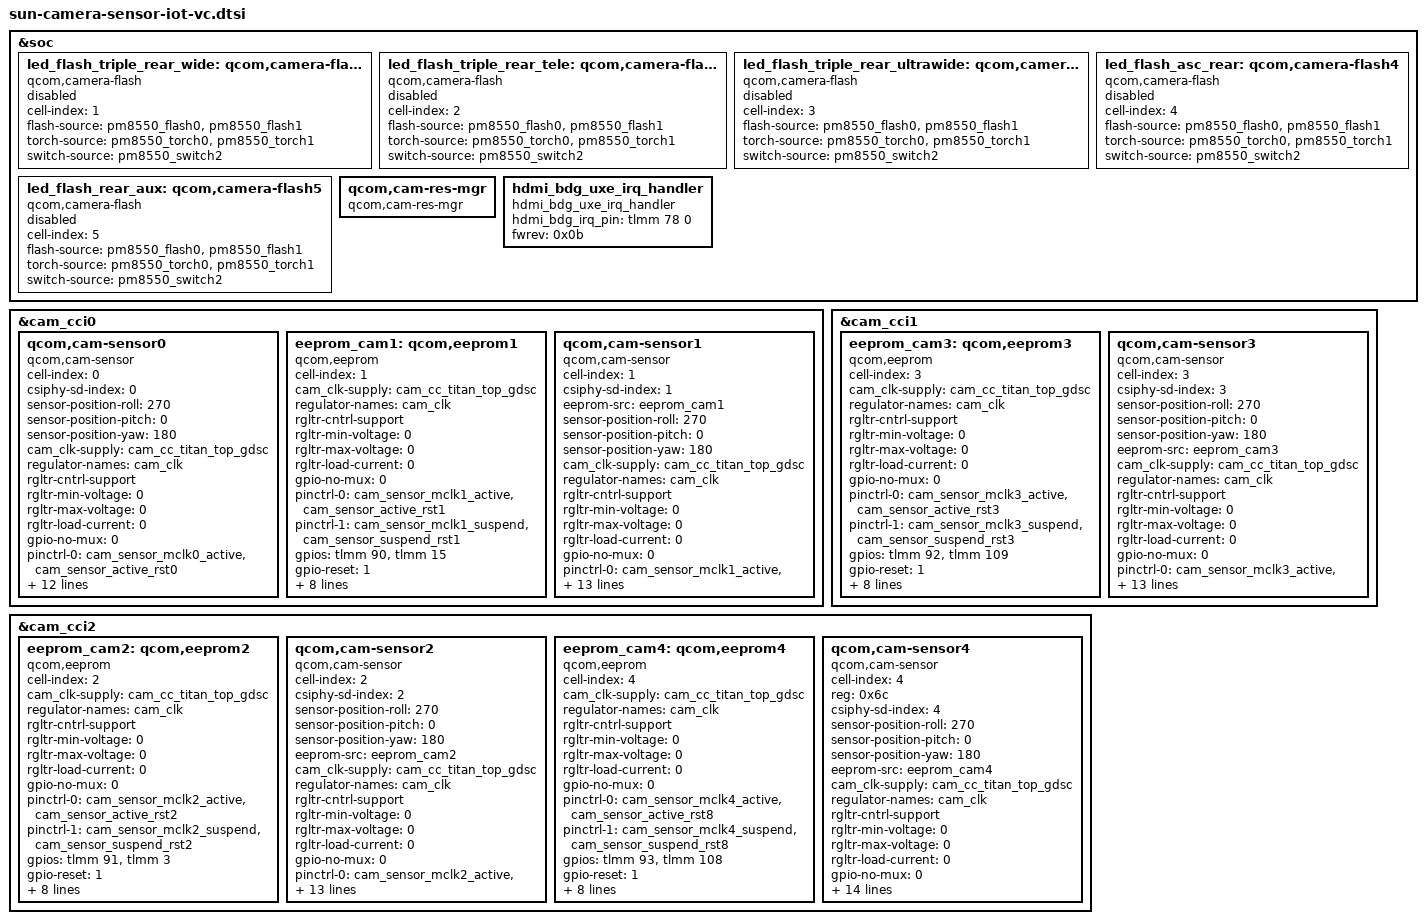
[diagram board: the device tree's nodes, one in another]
// SPDX-License-Identifier: BSD-3-Clause

/*
 * Copyright (c) Qualcomm Technologies, Inc. and/or its subsidiaries.
 */

#include <dt-bindings/msm-camera.h>
&soc {
	led_flash_triple_rear_wide: qcom,camera-flash1 {
		cell-index = <1>;
		compatible = "qcom,camera-flash";
		flash-source = <&pm8550_flash0 &pm8550_flash1>;
		torch-source = <&pm8550_torch0 &pm8550_torch1>;
		switch-source = <&pm8550_switch2>;
		status = "disabled";
	};

	led_flash_triple_rear_tele: qcom,camera-flash2 {
		cell-index = <2>;
		compatible = "qcom,camera-flash";
		flash-source = <&pm8550_flash0 &pm8550_flash1>;
		torch-source = <&pm8550_torch0 &pm8550_torch1>;
		switch-source = <&pm8550_switch2>;
		status = "disabled";
	};

	led_flash_triple_rear_ultrawide: qcom,camera-flash3 {
		cell-index = <3>;
		compatible = "qcom,camera-flash";
		flash-source = <&pm8550_flash0 &pm8550_flash1>;
		torch-source = <&pm8550_torch0 &pm8550_torch1>;
		switch-source = <&pm8550_switch2>;
		status = "disabled";
	};

	led_flash_asc_rear: qcom,camera-flash4 {
		cell-index = <4>;
		compatible = "qcom,camera-flash";
		flash-source = <&pm8550_flash0 &pm8550_flash1>;
		torch-source = <&pm8550_torch0 &pm8550_torch1>;
		switch-source = <&pm8550_switch2>;
		status = "disabled";
	};

	led_flash_rear_aux: qcom,camera-flash5 {
		cell-index = <5>;
		compatible = "qcom,camera-flash";
		flash-source = <&pm8550_flash0 &pm8550_flash1>;
		torch-source = <&pm8550_torch0 &pm8550_torch1>;
		switch-source = <&pm8550_switch2>;
		status = "disabled";
	};

	qcom,cam-res-mgr {
		compatible = "qcom,cam-res-mgr";
		status = "ok";
	};
};

&cam_cci0 {
	qcom,cam-sensor0 {
		cell-index = <0>;
		compatible = "qcom,cam-sensor";
		csiphy-sd-index = <0>;
		sensor-position-roll = <270>;
		sensor-position-pitch = <0>;
		sensor-position-yaw = <180>;

		cam_clk-supply = <&cam_cc_titan_top_gdsc>;
		regulator-names = "cam_clk";
		rgltr-cntrl-support;
		rgltr-min-voltage = < 0 >;
		rgltr-max-voltage = < 0 >;
		rgltr-load-current = < 0 >;

		gpio-no-mux = <0>;
		pinctrl-names = "cam_default", "cam_suspend";
		pinctrl-0 = <&cam_sensor_mclk0_active
				 &cam_sensor_active_rst0>;
		pinctrl-1 = <&cam_sensor_mclk0_suspend
				 &cam_sensor_suspend_rst0>;
		gpios = <&tlmm 89 0>,
			<&tlmm 13 0>;
		gpio-reset = <1>;
		gpio-req-tbl-num = <0 1>;
		gpio-req-tbl-flags = <1 0>;
		gpio-req-tbl-label = "CAMIF_MCLK0",
					"CAM_RESET0";
		cci-master = <CCI_MASTER_0>;
		clocks = <&cambistmclkcc CAM_BIST_MCLK_CC_MCLK0_CLK>;
		clock-names = "cam_clk";
		clock-cntl-level = "nominal";
		clock-rates = <24000000>;
		status = "ok";
	};


	eeprom_cam1: qcom,eeprom1 {
		cell-index = <1>;
		compatible = "qcom,eeprom";

		cam_clk-supply = <&cam_cc_titan_top_gdsc>;
		regulator-names = "cam_clk";
		rgltr-cntrl-support;
		rgltr-min-voltage = < 0 >;
		rgltr-max-voltage = < 0 >;
		rgltr-load-current = < 0 >;

		gpio-no-mux = <0>;
		pinctrl-names = "cam_default", "cam_suspend";
		pinctrl-0 = <&cam_sensor_mclk1_active
				&cam_sensor_active_rst1>;
		pinctrl-1 = <&cam_sensor_mclk1_suspend
				&cam_sensor_suspend_rst1>;
		gpios = <&tlmm 90 0>,
			<&tlmm 15 0>;
		gpio-reset = <1>;
		gpio-req-tbl-num = <0 1>;
		gpio-req-tbl-flags = <1 0>;
		gpio-req-tbl-label = "CAMIF_MCLK1",
					"CAM_RESET1";
		cci-master = <CCI_MASTER_1>;
		clocks = <&cambistmclkcc CAM_BIST_MCLK_CC_MCLK1_CLK>;
		clock-names = "cam_clk";
		clock-cntl-level = "nominal";
		clock-rates = <24000000>;
		status = "ok";
	};

	qcom,cam-sensor1 {
		cell-index = <1>;
		compatible = "qcom,cam-sensor";
		csiphy-sd-index = <1>;
		eeprom-src = <&eeprom_cam1>;
		sensor-position-roll = <270>;
		sensor-position-pitch = <0>;
		sensor-position-yaw = <180>;

		cam_clk-supply = <&cam_cc_titan_top_gdsc>;
		regulator-names = "cam_clk";
		rgltr-cntrl-support;
		rgltr-min-voltage = < 0 >;
		rgltr-max-voltage = < 0 >;
		rgltr-load-current = < 0 >;

		gpio-no-mux = <0>;
		pinctrl-names = "cam_default", "cam_suspend";
		pinctrl-0 = <&cam_sensor_mclk1_active
				 &cam_sensor_active_rst1>;
		pinctrl-1 = <&cam_sensor_mclk1_suspend
				 &cam_sensor_suspend_rst1>;
		gpios = <&tlmm 90 0>,
			<&tlmm 15 0>;
		gpio-reset = <1>;
		gpio-req-tbl-num = <0 1>;
		gpio-req-tbl-flags = <1 0>;
		gpio-req-tbl-label = "CAMIF_MCLK1",
					"CAM_RESET1";
		cci-master = <CCI_MASTER_1>;
		clocks = <&cambistmclkcc CAM_BIST_MCLK_CC_MCLK1_CLK>;
		clock-names = "cam_clk";
		clock-cntl-level = "nominal";
		clock-rates = <24000000>;
		status = "ok";
	};

};

&cam_cci1 {
	eeprom_cam3: qcom,eeprom3 {
		cell-index = <3>;
		compatible = "qcom,eeprom";

		cam_clk-supply = <&cam_cc_titan_top_gdsc>;
		regulator-names = "cam_clk";
		rgltr-cntrl-support;
		rgltr-min-voltage = < 0 >;
		rgltr-max-voltage = < 0 >;
		rgltr-load-current = < 0 >;

		gpio-no-mux = <0>;
		pinctrl-names = "cam_default", "cam_suspend";
		pinctrl-0 = <&cam_sensor_mclk3_active
				 &cam_sensor_active_rst3>;
		pinctrl-1 = <&cam_sensor_mclk3_suspend
				 &cam_sensor_suspend_rst3>;
		gpios = <&tlmm 92 0>,
			<&tlmm 109 0>;
		gpio-reset = <1>;
		gpio-req-tbl-num = <0 1>;
		gpio-req-tbl-flags = <1 0>;
		gpio-req-tbl-label = "CAMIF_MCLK3",
					"CAM_RESET3";
		cci-master = <CCI_MASTER_0>;
		clocks = <&cambistmclkcc CAM_BIST_MCLK_CC_MCLK3_CLK>;
		clock-names = "cam_clk";
		clock-cntl-level = "nominal";
		clock-rates = <24000000>;
		status = "ok";
	};

	qcom,cam-sensor3 {
		cell-index = <3>;
		compatible = "qcom,cam-sensor";
		csiphy-sd-index = <3>;
		sensor-position-roll = <270>;
		sensor-position-pitch = <0>;
		sensor-position-yaw = <180>;
		eeprom-src = <&eeprom_cam3>;

		cam_clk-supply = <&cam_cc_titan_top_gdsc>;
		regulator-names = "cam_clk";
		rgltr-cntrl-support;
		rgltr-min-voltage = < 0 >;
		rgltr-max-voltage = < 0 >;
		rgltr-load-current = < 0 >;

		gpio-no-mux = <0>;
		pinctrl-names = "cam_default", "cam_suspend";
		pinctrl-0 = <&cam_sensor_mclk3_active
				 &cam_sensor_active_rst3>;
		pinctrl-1 = <&cam_sensor_mclk3_suspend
				 &cam_sensor_suspend_rst3>;
		gpios = <&tlmm 92 0>,
			<&tlmm 109 0>;
		gpio-reset = <1>;
		gpio-req-tbl-num = <0 1>;
		gpio-req-tbl-flags = <1 0>;
		gpio-req-tbl-label = "CAMIF_MCLK3",
					"CAM_RESET3";
		cci-master = <CCI_MASTER_0>;
		clocks = <&cambistmclkcc CAM_BIST_MCLK_CC_MCLK3_CLK>;
		clock-names = "cam_clk";
		clock-cntl-level = "nominal";
		clock-rates = <24000000>;
		status = "ok";
	};

};

&cam_cci2 {
	eeprom_cam2: qcom,eeprom2 {
		cell-index = <2>;
		compatible = "qcom,eeprom";

		cam_clk-supply = <&cam_cc_titan_top_gdsc>;
		regulator-names = "cam_clk";
		rgltr-cntrl-support;
		rgltr-min-voltage = < 0 >;
		rgltr-max-voltage = < 0 >;
		rgltr-load-current = < 0 >;

		gpio-no-mux = <0>;
		pinctrl-names = "cam_default", "cam_suspend";
		pinctrl-0 = <&cam_sensor_mclk2_active
				 &cam_sensor_active_rst2>;
		pinctrl-1 = <&cam_sensor_mclk2_suspend
				 &cam_sensor_suspend_rst2>;
		gpios = <&tlmm 91 0>,
			<&tlmm 3 0>;
		gpio-reset = <1>;
		gpio-req-tbl-num = <0 1>;
		gpio-req-tbl-flags = <1 0>;
		gpio-req-tbl-label = "CAMIF_MCLK2",
					"CAM_RESET2";
		cci-master = <CCI_MASTER_1>;
		clocks = <&cambistmclkcc CAM_BIST_MCLK_CC_MCLK2_CLK>;
		clock-names = "cam_clk";
		clock-cntl-level = "nominal";
		clock-rates = <24000000>;
		status = "ok";
	};

	qcom,cam-sensor2 {
		cell-index = <2>;
		compatible = "qcom,cam-sensor";
		csiphy-sd-index = <2>;
		sensor-position-roll = <270>;
		sensor-position-pitch = <0>;
		sensor-position-yaw = <180>;
		eeprom-src = <&eeprom_cam2>;

		cam_clk-supply = <&cam_cc_titan_top_gdsc>;
		regulator-names = "cam_clk";
		rgltr-cntrl-support;
		rgltr-min-voltage = < 0 >;
		rgltr-max-voltage = < 0 >;
		rgltr-load-current = < 0 >;

		gpio-no-mux = <0>;
		pinctrl-names = "cam_default", "cam_suspend";
		pinctrl-0 = <&cam_sensor_mclk2_active
				 &cam_sensor_active_rst2>;
		pinctrl-1 = <&cam_sensor_mclk2_suspend
				 &cam_sensor_suspend_rst2>;
		gpios = <&tlmm 91 0>,
			<&tlmm 3 0>;
		gpio-reset = <1>;
		gpio-req-tbl-num = <0 1>;
		gpio-req-tbl-flags = <1 0>;
		gpio-req-tbl-label = "CAMIF_MCLK2",
					"CAM_RESET2";
		cci-master = <CCI_MASTER_1>;
		clocks = <&cambistmclkcc CAM_BIST_MCLK_CC_MCLK2_CLK>;
		clock-names = "cam_clk";
		clock-cntl-level = "nominal";
		clock-rates = <24000000>;
		status = "ok";
	};

	eeprom_cam4: qcom,eeprom4 {
		cell-index = <4>;
		compatible = "qcom,eeprom";

		cam_clk-supply = <&cam_cc_titan_top_gdsc>;
		regulator-names = "cam_clk";
		rgltr-cntrl-support;
		rgltr-min-voltage = < 0 >;
		rgltr-max-voltage = < 0 >;
		rgltr-load-current = < 0 >;

		gpio-no-mux = <0>;
		pinctrl-names = "cam_default", "cam_suspend";
		pinctrl-0 = <&cam_sensor_mclk4_active
				 &cam_sensor_active_rst8>;
		pinctrl-1 = <&cam_sensor_mclk4_suspend
				 &cam_sensor_suspend_rst8>;
		gpios = <&tlmm 93 0>,
			<&tlmm 108 0>;
		gpio-reset = <1>;
		gpio-req-tbl-num = <0 1>;
		gpio-req-tbl-flags = <1 0>;
		gpio-req-tbl-label = "CAMIF_MCLK4",
					"CAM_RESET8";
		cci-master = <CCI_MASTER_0>;
		clocks = <&cambistmclkcc CAM_BIST_MCLK_CC_MCLK4_CLK>;
		clock-names = "cam_clk";
		clock-cntl-level = "nominal";
		clock-rates = <24000000>;
		status = "ok";
	};

	qcom,cam-sensor4 {
		cell-index = <4>;
		reg = <0x6c>;
		compatible = "qcom,cam-sensor";
		csiphy-sd-index = <4>;
		sensor-position-roll = <270>;
		sensor-position-pitch = <0>;
		sensor-position-yaw = <180>;
		eeprom-src = <&eeprom_cam4>;

		cam_clk-supply = <&cam_cc_titan_top_gdsc>;
		regulator-names = "cam_clk";
		rgltr-cntrl-support;
		rgltr-min-voltage = < 0 >;
		rgltr-max-voltage = < 0 >;
		rgltr-load-current = < 0 >;

		gpio-no-mux = <0>;
		pinctrl-names = "cam_default", "cam_suspend";
		pinctrl-0 = <&cam_sensor_mclk4_active
				 &cam_sensor_active_rst8>;
		pinctrl-1 = <&cam_sensor_mclk4_suspend
				 &cam_sensor_suspend_rst8>;
		gpios = <&tlmm 93 0>,
			<&tlmm 108 0>;
		gpio-reset = <1>;
		gpio-req-tbl-num = <0 1>;
		gpio-req-tbl-flags = <1 0>;
		gpio-req-tbl-label = "CAMIF_MCLK4",
					"CAM_RESET8";
		cci-master = <CCI_MASTER_0>;
		clocks = <&cambistmclkcc CAM_BIST_MCLK_CC_MCLK4_CLK>;
		clock-names = "cam_clk";
		clock-cntl-level = "nominal";
		clock-rates = <24000000>;
		status = "ok";
	};
};

&soc {
	hdmi_bdg_uxe_irq_handler: hdmi_bdg_uxe_irq_handler {
		compatible = "hdmi_bdg_uxe_irq_handler";
		hdmi_bdg_irq_pin = <&tlmm 78 0>;
		fwrev = <0x0b>;
	};
};
